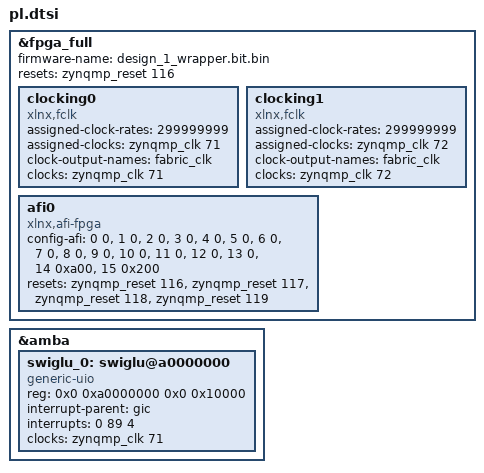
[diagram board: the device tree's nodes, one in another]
/*
 * CAUTION: This file is automatically generated by Xilinx.
 * Version: XSCT 2025.1
 * Today is: Fri Apr  3 13:39:45 2026
 */


/dts-v1/;
/plugin/;
&fpga_full {
	firmware-name = "design_1_wrapper.bit.bin";
	resets = <&zynqmp_reset 116>;
	clocking0: clocking0 {
		#clock-cells = <0>;
		assigned-clock-rates = <299999999>;
		assigned-clocks = <&zynqmp_clk 71>;
		clock-output-names = "fabric_clk";
		clocks = <&zynqmp_clk 71>;
		compatible = "xlnx,fclk";
	};
	clocking1: clocking1 {
		#clock-cells = <0>;
		assigned-clock-rates = <299999999>;
		assigned-clocks = <&zynqmp_clk 72>;
		clock-output-names = "fabric_clk";
		clocks = <&zynqmp_clk 72>;
		compatible = "xlnx,fclk";
	};
	afi0: afi0 {
		compatible = "xlnx,afi-fpga";
		config-afi = < 0 0>, <1 0>, <2 0>, <3 0>, <4 0>, <5 0>, <6 0>, <7 0>, <8 0>, <9 0>, <10 0>, <11 0>, <12 0>, <13 0>, <14 0xa00>, <15 0x200>;
		resets = <&zynqmp_reset 116>, <&zynqmp_reset 117>, <&zynqmp_reset 118>, <&zynqmp_reset 119>;
	};
};
&amba {
	#address-cells = <2>;
	#size-cells = <2>;
	swiglu_0: swiglu@a0000000 {
		compatible = "generic-uio";
		reg = <0x0 0xa0000000 0x0 0x10000>;
		interrupt-parent = <&gic>;
		interrupts = <0 89 4>;
		interrupt-names = "interrupt";
		clocks = <&zynqmp_clk 71>;
	};
};
